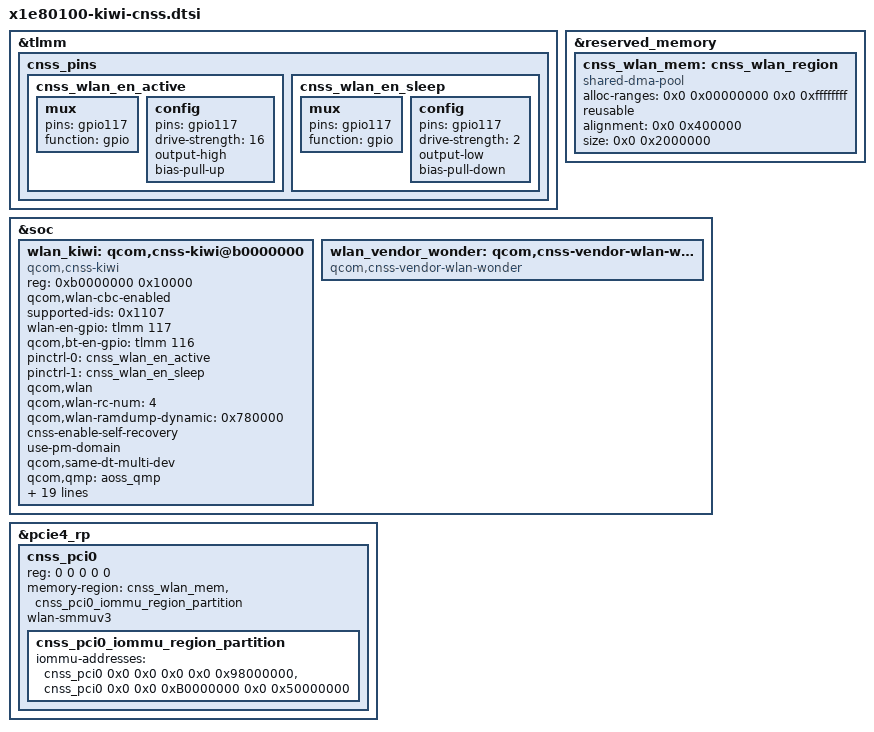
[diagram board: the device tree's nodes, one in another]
// SPDX-License-Identifier: BSD-3-Clause

/*
 * Copyright (c) Qualcomm Technologies, Inc. and/or its subsidiaries.
 */

#include <dt-bindings/interconnect/qcom,x1e80100-rpmh.h>

&tlmm {
	cnss_pins {
		cnss_wlan_en_active: cnss_wlan_en_active {
			mux {
				pins = "gpio117";
				function = "gpio";
			};

			config {
				pins = "gpio117";
				drive-strength = <16>;
				output-high;
				bias-pull-up;
			};
		};

		cnss_wlan_en_sleep: cnss_wlan_en_sleep {
			mux {
				pins = "gpio117";
				function = "gpio";
			};

			config {
				pins = "gpio117";
				drive-strength = <2>;
				output-low;
				bias-pull-down;
			};
		};
	};
};

&reserved_memory {
	cnss_wlan_mem: cnss_wlan_region {
		compatible = "shared-dma-pool";
		alloc-ranges = <0x0 0x00000000 0x0 0xffffffff>;
		reusable;
		alignment = <0x0 0x400000>;
		size = <0x0 0x2000000>;
	};
};

&soc {
	wlan_kiwi: qcom,cnss-kiwi@b0000000 {
		compatible = "qcom,cnss-kiwi";
		reg = <0xb0000000 0x10000>;
		reg-names = "smmu_iova_ipa";
		qcom,wlan-cbc-enabled;
		supported-ids = <0x1107>;
		wlan-en-gpio = <&tlmm 117 0>;
		qcom,bt-en-gpio = <&tlmm 116 0>;
		pinctrl-names = "wlan_en_active", "wlan_en_sleep";
		pinctrl-0 = <&cnss_wlan_en_active>;
		pinctrl-1 = <&cnss_wlan_en_sleep>;
		qcom,wlan;
		qcom,wlan-rc-num = <4>;
		qcom,wlan-ramdump-dynamic = <0x780000>;
		cnss-enable-self-recovery;
		use-pm-domain;
		qcom,same-dt-multi-dev;
		qcom,qmp = <&aoss_qmp>;
		vdd-wlan-m2-supply = <&vreg_wlan_3p3>;
		qcom,vdd-wlan-m2-config = <3300000 3300000 0 0 0>;
		/* 1: board-id from PCIe config space (SSID/SVID) */
		qcom,board-id-src = <1>;
		vdd-wlan-io-supply = <&L15B>;
		qcom,vdd-wlan-io-config = <1800000 1800000 0 0 0>;

		interconnects =
		<&pcie_north_anoc MASTER_PCIE_4 &pcie_center_anoc SLAVE_ANOC_PCIE_GEM_NOC>,
		<&gem_noc MASTER_ANOC_PCIE_GEM_NOC &mc_virt SLAVE_EBI1>;
		interconnect-names = "pcie_to_memnoc", "memnoc_to_ddr";

		qcom,icc-path-count = <2>;
		qcom,bus-bw-cfg-count = <9>;
		qcom,bus-bw-cfg =
		/** ICC Path 1 **/
		<0 0>, /* no vote */
		/* idle: 0-18 Mbps snoc/anoc: 200 Mhz */
		<2250 12700000>,
		/* low: 18-60 Mbps snoc/anoc: 200 Mhz */
		<7500 12700000>,
		/* medium: 60-240 Mbps snoc/anoc: 200 Mhz */
		<30000 12700000>,
		/* high: 240-1200 Mbps snoc/anoc: 200 Mhz */
		<100000 12700000>,
		/* very high: > 1200 Mbps snoc/anoc: 403 Mhz */
		<175000 25600000>,
		/* ultra high: DBS mode snoc/anoc: 403 Mhz */
		<312500 25600000>,
		/* super high: DBS mode snoc/anoc: 533 Mhz */
		<587500 33920000>,
		/* low (latency critical): 18-60 Mbps snoc/anoc: 200 Mhz */
		<7500 12700000>,

		/** ICC Path 2 **/
		<0 0>,
		/* idle: 0-18 Mbps ddr: 547.2 MHz */
		<2250 2180000>,
		/* low: 18-60 Mbps ddr: 547.2 MHz */
		<7500 2180000>,
		/* medium: 60-240 Mbps ddr: 547.2 MHz */
		<30000 2180000>,
		/* high: 240-1200 Mbps ddr: 547.2 MHz */
		<100000 2180000>,
		/* very high: > 1200 Mbps ddr: 1555 MHz */
		<175000 6220000>,
		/* ultra high: DBS mode ddr: 2092 MHz */
		<312500 8368000>,
		/* super high: DBS mode ddr: 3.2 GHz */
		<587500 12000000>,
		/* low (latency critical): 18-60 Mbps ddr: 547.2 MHz */
		<7500 2180000>;
	};

	wlan_vendor_wonder: qcom,cnss-vendor-wlan-wonder {
		compatible = "qcom,cnss-vendor-wlan-wonder";
		status = "okay";
	};
};

&pcie4_rp {
	cnss_pci0: cnss_pci0 {
		reg = <0 0 0 0 0>;
		memory-region =
			<&cnss_wlan_mem &cnss_pci0_iommu_region_partition>;

		#address-cells = <1>;
		#size-cells = <1>;
		wlan-smmuv3;

		cnss_pci0_iommu_region_partition:
		cnss_pci0_iommu_region_partition {
			iommu-addresses =
				<&cnss_pci0 0x0 0x0 0x0 0x0 0x98000000>,
				<&cnss_pci0 0x0 0x0 0xB0000000 0x0 0x50000000>;
		};
	};
};
